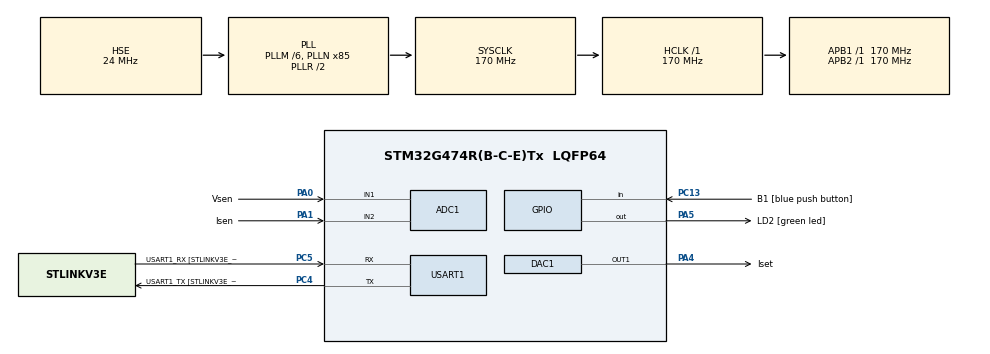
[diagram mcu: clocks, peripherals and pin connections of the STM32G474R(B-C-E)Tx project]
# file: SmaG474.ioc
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ADC1.Channel-0\#ChannelRegularConversion=ADC_CHANNEL_1
ADC1.Channel-2\#ChannelRegularConversion=ADC_CHANNEL_2
ADC1.ContinuousConvMode=ENABLE
ADC1.DMAContinuousRequests=ENABLE
ADC1.EOCSelection=ADC_EOC_SEQ_CONV
ADC1.ExternalTrigConv=ADC_SOFTWARE_START
ADC1.NbrOfConversion=2
ADC1.NbrOfConversionFlag=1
ADC1.OffsetNumber-0\#ChannelRegularConversion=ADC_OFFSET_NONE
ADC1.OffsetNumber-2\#ChannelRegularConversion=ADC_OFFSET_NONE
ADC1.OversamplingMode=ENABLE
ADC1.Rank-0\#ChannelRegularConversion=1
ADC1.Rank-2\#ChannelRegularConversion=2
ADC1.Ratio=ADC_OVERSAMPLING_RATIO_256
ADC1.RightBitShift=ADC_RIGHTBITSHIFT_4
ADC1.SamplingTime-0\#ChannelRegularConversion=ADC_SAMPLETIME_2CYCLES_5
ADC1.SamplingTime-2\#ChannelRegularConversion=ADC_SAMPLETIME_2CYCLES_5
ADC1.master=1
Dma.ADC1.0.Direction=DMA_PERIPH_TO_MEMORY
Dma.ADC1.0.EventEnable=DISABLE
Dma.ADC1.0.Instance=DMA1_Channel1
Dma.ADC1.0.MemDataAlignment=DMA_MDATAALIGN_HALFWORD
Dma.ADC1.0.MemInc=DMA_MINC_ENABLE
Dma.ADC1.0.Mode=DMA_CIRCULAR
Dma.ADC1.0.PeriphDataAlignment=DMA_PDATAALIGN_HALFWORD
Dma.ADC1.0.PeriphInc=DMA_PINC_DISABLE
Dma.ADC1.0.Polarity=HAL_DMAMUX_REQ_GEN_RISING
Dma.ADC1.0.Priority=DMA_PRIORITY_LOW
Dma.ADC1.0.RequestNumber=1
Dma.ADC1.0.SignalID=NONE
Dma.ADC1.0.SyncEnable=DISABLE
Dma.ADC1.0.SyncPolarity=HAL_DMAMUX_SYNC_NO_EVENT
Dma.ADC1.0.SyncRequestNumber=1
Dma.ADC1.0.SyncSignalID=NONE
Dma.Request0=ADC1
Mcu.Family=STM32G4
Mcu.Name=STM32G474R(B-C-E)Tx
Mcu.Package=LQFP64
NVIC.DMA1_Channel1_IRQn=true\:0\:0\:false\:false\:true\:false\:true
NVIC.PriorityGroup=NVIC_PRIORITYGROUP_4
PA0.GPIO_Label=Vsen
PA0.Mode=IN1-Single-Ended
PA0.Signal=ADC1_IN1
PA1.GPIO_Label=Isen
PA1.Mode=IN2-Single-Ended
PA1.Signal=ADC1_IN2
PA13.GPIO_Label=T_SWDIO
PA13.Mode=Serial_Wire
PA13.Signal=SYS_JTMS-SWDIO
PA14.GPIO_Label=T_SWCLK
PA14.Mode=Serial_Wire
PA14.Signal=SYS_JTCK-SWCLK
PA4.GPIO_Label=Iset
PA4.Signal=COMP_DAC11_group
PA5.GPIO_Label=LD2 [green led]
PA5.Signal=GPIO_Output
PB3.GPIO_Label=T_SWO
PB3.Signal=SYS_JTDO-SWO
PC13.GPIO_Label=B1 [blue push button]
PC13.Signal=GPIO_Input
PC14-OSC32_IN.Mode=LSE-External-Oscillator
PC14-OSC32_IN.Signal=RCC_OSC32_IN
PC15-OSC32_OUT.Mode=LSE-External-Oscillator
PC15-OSC32_OUT.Signal=RCC_OSC32_OUT
PC4.GPIO_Label=USART1_TX [STLINKV3E_VCP_RX]
PC4.Mode=Asynchronous
PC4.Signal=USART1_TX
PC5.GPIO_Label=USART1_RX [STLINKV3E_VCP_TX]
PC5.Mode=Asynchronous
PC5.Signal=USART1_RX
PF0-OSC_IN.Mode=HSE-External-Oscillator
PF0-OSC_IN.Signal=RCC_OSC_IN
PF1-OSC_OUT.Mode=HSE-External-Oscillator
PF1-OSC_OUT.Signal=RCC_OSC_OUT
ProjectManager.HeapSize=0x200
ProjectManager.StackSize=0x400
ProjectManager.TargetToolchain=Makefile
RCC.ADC12Freq_Value=170000000
RCC.ADC345Freq_Value=170000000
RCC.AHBFreq_Value=170000000
RCC.APB1Freq_Value=170000000
RCC.APB1TimFreq_Value=170000000
RCC.APB2Freq_Value=170000000
RCC.APB2TimFreq_Value=170000000
RCC.CortexFreq_Value=170000000
RCC.EXTERNAL_CLOCK_VALUE=12288000
RCC.HCLKFreq_Value=170000000
RCC.HSE_VALUE=24000000
RCC.HSI48_VALUE=48000000
RCC.HSI_VALUE=16000000
RCC.PLLM=RCC_PLLM_DIV6
RCC.PLLN=85
RCC.PLLSourceVirtual=RCC_PLLSOURCE_HSE
RCC.RTCClockSelection=RCC_RTCCLKSOURCE_LSE
RCC.SYSCLKFreq_VALUE=170000000
RCC.SYSCLKSource=RCC_SYSCLKSOURCE_PLLCLK
RCC.USBFreq_Value=170000000
RCC.VCOOutputFreq_Value=340000000
SH.COMP_DAC11_group.0=DAC1_OUT1,DAC_OUT1
TIM2.PeriodNoDither=999
TIM2.Prescaler=169
TIM2.TIM_MasterOutputTrigger=TIM_TRGO_UPDATE
USART1.VirtualMode-Asynchronous=VM_ASYNC
USART1.WordLength=WORDLENGTH_8B
VP_SYS_VS_DBSignals.Mode=DisableDeadBatterySignals
VP_TIM2_VS_ClockSourceINT.Mode=Internal
board=NUCLEO-G474RE

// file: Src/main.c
/* USER CODE BEGIN Header */
/**
 ******************************************************************************
 * @file           : main.c
 * @brief          : Main program body
 ******************************************************************************
 * @attention
 *
 * <h2><center>&copy; Copyright (c) 2020 STMicroelectronics.
 * All rights reserved.</center></h2>
 *
 * This software component is licensed by ST under BSD 3-Clause license,
 * the "License"; You may not use this file except in compliance with the
 * License. You may obtain a copy of the License at:
 *                        opensource.org/licenses/BSD-3-Clause
 *
 ******************************************************************************
 */
/* USER CODE END Header */

#include "main.h"
#include "adc.h"
#include "dac.h"
#include "dma.h"
#include "tim.h"
#include "usart.h"
#include "gpio.h"

/* USER CODE BEGIN Includes */
#include "smaAFE.h"
/* USER CODE END Includes */

void SystemClock_Config(void);

int main(void)
{

  /* MCU Configuration--------------------------------------------------------*/

  /* Reset of all peripherals, Initializes the Flash interface and the Systick. */
  HAL_Init();

  /* Configure the system clock */
  SystemClock_Config();

  /* Initialize all configured peripherals */
  MX_GPIO_Init();
  MX_DMA_Init();
  MX_ADC1_Init();
  MX_DAC1_Init();
  MX_USART1_UART_Init();
  MX_TIM2_Init();
  /* USER CODE BEGIN 2 */
    smaAfeInit();
    uint32_t lastTick = HAL_GetTick();
  /* USER CODE END 2 */

  /* Infinite loop */
    while (1)
    {

    /* USER CODE BEGIN 3 */
    if (HAL_GetTick() - lastTick > 10)
    {
        smaAfeLoop();
        lastTick = HAL_GetTick();
    }
    }
  /* USER CODE END 3 */
}

void SystemClock_Config(void)
{
  RCC_OscInitTypeDef RCC_OscInitStruct = {0};
  RCC_ClkInitTypeDef RCC_ClkInitStruct = {0};
  RCC_PeriphCLKInitTypeDef PeriphClkInit = {0};

  /** Configure the main internal regulator output voltage
  */
  HAL_PWREx_ControlVoltageScaling(PWR_REGULATOR_VOLTAGE_SCALE1_BOOST);
  /** Initializes the CPU, AHB and APB busses clocks
  */
  RCC_OscInitStruct.OscillatorType = RCC_OSCILLATORTYPE_HSE;
  RCC_OscInitStruct.HSEState = RCC_HSE_ON;
  RCC_OscInitStruct.PLL.PLLState = RCC_PLL_ON;
  RCC_OscInitStruct.PLL.PLLSource = RCC_PLLSOURCE_HSE;
  RCC_OscInitStruct.PLL.PLLM = RCC_PLLM_DIV6;
  RCC_OscInitStruct.PLL.PLLN = 85;
  RCC_OscInitStruct.PLL.PLLP = RCC_PLLP_DIV2;
  RCC_OscInitStruct.PLL.PLLQ = RCC_PLLQ_DIV2;
  RCC_OscInitStruct.PLL.PLLR = RCC_PLLR_DIV2;
  if (HAL_RCC_OscConfig(&RCC_OscInitStruct) != HAL_OK)
  {
    Error_Handler();
  }
  /** Initializes the CPU, AHB and APB busses clocks
  */
  RCC_ClkInitStruct.ClockType = RCC_CLOCKTYPE_HCLK|RCC_CLOCKTYPE_SYSCLK
                              |RCC_CLOCKTYPE_PCLK1|RCC_CLOCKTYPE_PCLK2;
  RCC_ClkInitStruct.SYSCLKSource = RCC_SYSCLKSOURCE_PLLCLK;
  RCC_ClkInitStruct.AHBCLKDivider = RCC_SYSCLK_DIV1;
  RCC_ClkInitStruct.APB1CLKDivider = RCC_HCLK_DIV1;
  RCC_ClkInitStruct.APB2CLKDivider = RCC_HCLK_DIV1;

  if (HAL_RCC_ClockConfig(&RCC_ClkInitStruct, FLASH_LATENCY_8) != HAL_OK)
  {
    Error_Handler();
  }
  /** Initializes the peripherals clocks
  */
  PeriphClkInit.PeriphClockSelection = RCC_PERIPHCLK_USART1|RCC_PERIPHCLK_ADC12;
  PeriphClkInit.Usart1ClockSelection = RCC_USART1CLKSOURCE_PCLK2;
  PeriphClkInit.Adc12ClockSelection = RCC_ADC12CLKSOURCE_SYSCLK;
  if (HAL_RCCEx_PeriphCLKConfig(&PeriphClkInit) != HAL_OK)
  {
    Error_Handler();
  }
}

void Error_Handler(void)
{
  /* USER CODE BEGIN Error_Handler_Debug */
    /* User can add his own implementation to report the HAL error return state
     */

  /* USER CODE END Error_Handler_Debug */
}

#ifdef  USE_FULL_ASSERT
/**
  * @brief  Reports the name of the source file and the source line number
  *         where the assert_param error has occurred.
  * @param  file: pointer to the source file name
  * @param  line: assert_param error line source number
  * @retval None
  */
void assert_failed(uint8_t *file, uint32_t line)
{
  /* USER CODE BEGIN 6 */
    /* User can add his own implementation to report the file name and line
       number, tex: printf("Wrong parameters value: file %s on line %d\r\n",
       file, line) */
  /* USER CODE END 6 */
}
#endif /* USE_FULL_ASSERT */

/************************ (C) COPYRIGHT STMicroelectronics *****END OF FILE****/
